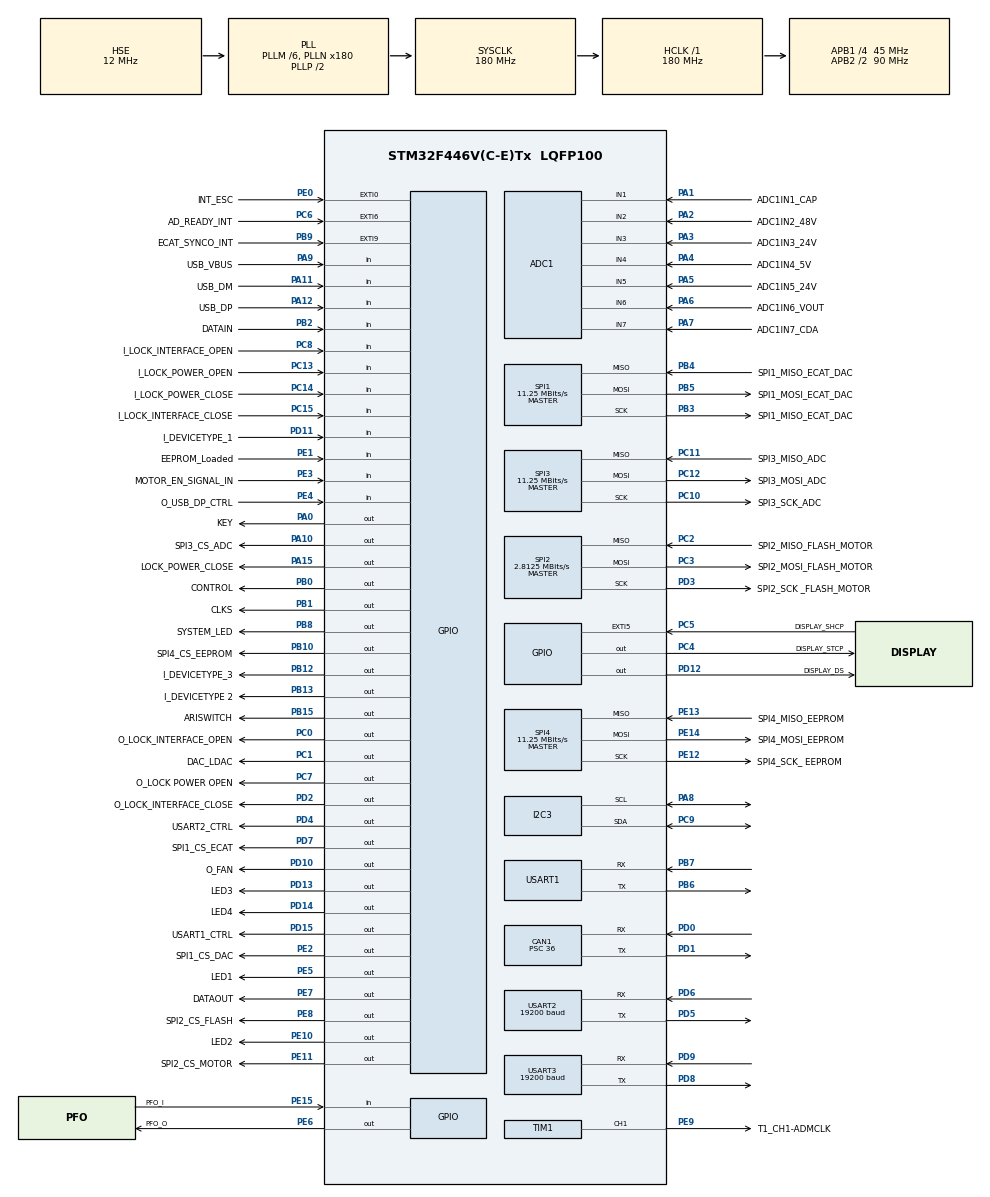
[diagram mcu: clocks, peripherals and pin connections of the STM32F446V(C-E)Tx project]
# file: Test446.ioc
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ADC1.Channel-0\#ChannelRegularConversion=ADC_CHANNEL_1
ADC1.Channel-1\#ChannelRegularConversion=ADC_CHANNEL_1
ADC1.Channel-2\#ChannelRegularConversion=ADC_CHANNEL_1
ADC1.Channel-3\#ChannelRegularConversion=ADC_CHANNEL_1
ADC1.Channel-4\#ChannelRegularConversion=ADC_CHANNEL_1
ADC1.Channel-5\#ChannelRegularConversion=ADC_CHANNEL_1
ADC1.Channel-6\#ChannelRegularConversion=ADC_CHANNEL_1
ADC1.ContinuousConvMode=ENABLE
ADC1.master=1
ADC1.NbrOfConversion=7
ADC1.NbrOfConversionFlag=1
ADC1.Rank-0\#ChannelRegularConversion=1
ADC1.Rank-1\#ChannelRegularConversion=2
ADC1.Rank-2\#ChannelRegularConversion=3
ADC1.Rank-3\#ChannelRegularConversion=4
ADC1.Rank-4\#ChannelRegularConversion=5
ADC1.Rank-5\#ChannelRegularConversion=6
ADC1.Rank-6\#ChannelRegularConversion=7
ADC1.SamplingTime-0\#ChannelRegularConversion=ADC_SAMPLETIME_3CYCLES
ADC1.SamplingTime-1\#ChannelRegularConversion=ADC_SAMPLETIME_3CYCLES
ADC1.SamplingTime-2\#ChannelRegularConversion=ADC_SAMPLETIME_3CYCLES
ADC1.SamplingTime-3\#ChannelRegularConversion=ADC_SAMPLETIME_3CYCLES
ADC1.SamplingTime-4\#ChannelRegularConversion=ADC_SAMPLETIME_3CYCLES
ADC1.SamplingTime-5\#ChannelRegularConversion=ADC_SAMPLETIME_3CYCLES
ADC1.SamplingTime-6\#ChannelRegularConversion=ADC_SAMPLETIME_3CYCLES
ADC1.ScanConvMode=ENABLE
board=custom
CAN1.ABOM=ENABLE
CAN1.BS1=CAN_BS1_4TQ
CAN1.BS2=CAN_BS2_5TQ
CAN1.CalculateBaudRate=125000
CAN1.CalculateTimeBit=8000
CAN1.CalculateTimeQuantum=800.0
CAN1.NART=ENABLE
CAN1.Prescaler=36
CAN1.RFLM=ENABLE
CAN1.TTCM=ENABLE
Dma.ADC1.0.Direction=DMA_PERIPH_TO_MEMORY
Dma.ADC1.0.FIFOMode=DMA_FIFOMODE_DISABLE
Dma.ADC1.0.Instance=DMA2_Stream0
Dma.ADC1.0.MemDataAlignment=DMA_MDATAALIGN_WORD
Dma.ADC1.0.MemInc=DMA_MINC_ENABLE
Dma.ADC1.0.Mode=DMA_CIRCULAR
Dma.ADC1.0.PeriphDataAlignment=DMA_PDATAALIGN_WORD
Dma.ADC1.0.PeriphInc=DMA_PINC_DISABLE
Dma.ADC1.0.Priority=DMA_PRIORITY_LOW
Dma.I2C3_RX.1.Direction=DMA_PERIPH_TO_MEMORY
Dma.I2C3_RX.1.FIFOMode=DMA_FIFOMODE_DISABLE
Dma.I2C3_RX.1.Instance=DMA1_Stream1
Dma.I2C3_RX.1.MemDataAlignment=DMA_MDATAALIGN_BYTE
Dma.I2C3_RX.1.MemInc=DMA_MINC_ENABLE
Dma.I2C3_RX.1.Mode=DMA_NORMAL
Dma.I2C3_RX.1.PeriphDataAlignment=DMA_PDATAALIGN_BYTE
Dma.I2C3_RX.1.PeriphInc=DMA_PINC_DISABLE
Dma.I2C3_RX.1.Priority=DMA_PRIORITY_LOW
Dma.I2C3_TX.2.Direction=DMA_MEMORY_TO_PERIPH
Dma.I2C3_TX.2.FIFOMode=DMA_FIFOMODE_DISABLE
Dma.I2C3_TX.2.Instance=DMA1_Stream4
Dma.I2C3_TX.2.MemDataAlignment=DMA_MDATAALIGN_BYTE
Dma.I2C3_TX.2.MemInc=DMA_MINC_ENABLE
Dma.I2C3_TX.2.Mode=DMA_NORMAL
Dma.I2C3_TX.2.PeriphDataAlignment=DMA_PDATAALIGN_BYTE
Dma.I2C3_TX.2.PeriphInc=DMA_PINC_DISABLE
Dma.I2C3_TX.2.Priority=DMA_PRIORITY_LOW
Dma.Request0=ADC1
Dma.Request1=I2C3_RX
Dma.Request2=I2C3_TX
FREERTOS.INCLUDE_vTaskCleanUpResources=0
FREERTOS.Tasks01=defaultTask,40,512,StartDefaultTask,As weak,NULL,Dynamic,NULL,NULL;LDETask,8,128,StartTask03,As weak,NULL,Dynamic,NULL,NULL;RS485Task,40,256,TASK_RS485,As weak,NULL,Dynamic,NULL,NULL;DeviceNetTask,24,512,TASK_DeviceNet,As weak,NULL,Dynamic,NULL,NULL;HcmsTask,8,128,Task_Hcms,As weak,NULL,Dynamic,NULL,NULL;RS232Task,40,256,TASK_RS232,As weak,NULL,Dynamic,NULL,NULL;FlowEstTAask,16,128,Task_FlowEst,As weak,NULL,Dynamic,NULL,NULL;AdaptiveTask,16,256,Task_Adapyive,As weak,NULL,Dynamic,NULL,NULL;EtherCATTask,40,256,TASK_EtherCAT,As weak,NULL,Dynamic,NULL,NULL;RS485_2,40,256,TASK_RS485_2,As weak,NULL,Dynamic,NULL,NULL;USBTask,40,768,TASK_USB,As weak,NULL,Dynamic,NULL,NULL;USBIOTask,40,512,TASK_USB_IO,As weak,NULL,Dynamic,NULL,NULL
FREERTOS.TOTAL_HEAP_SIZE=20480
IWDG.Prescaler=IWDG_PRESCALER_32
Mcu.Family=STM32F4
Mcu.Name=STM32F446V(C-E)Tx
Mcu.Package=LQFP100
NVIC.CAN1_RX0_IRQn=true\:5\:0\:false\:false\:true\:true\:true\:true\:true
NVIC.DMA1_Stream1_IRQn=true\:5\:0\:false\:false\:true\:true\:false\:true\:true
NVIC.DMA1_Stream4_IRQn=true\:5\:0\:false\:false\:true\:true\:false\:true\:true
NVIC.DMA2_Stream0_IRQn=true\:5\:0\:false\:false\:true\:true\:false\:true\:true
NVIC.I2C3_ER_IRQn=true\:5\:0\:false\:false\:true\:true\:true\:true\:true
NVIC.I2C3_EV_IRQn=true\:5\:0\:false\:false\:true\:true\:true\:true\:true
NVIC.OTG_FS_IRQn=true\:5\:0\:false\:false\:true\:true\:true\:true\:true
NVIC.PriorityGroup=NVIC_PRIORITYGROUP_4
NVIC.TIM1_UP_TIM10_IRQn=true\:5\:0\:false\:false\:true\:true\:true\:true\:true
NVIC.TIM3_IRQn=true\:5\:0\:false\:false\:true\:true\:true\:true\:true
NVIC.TIM7_IRQn=true\:15\:0\:false\:false\:true\:false\:false\:true\:true
NVIC.TimeBase=TIM7_IRQn
NVIC.TimeBaseIP=TIM7
NVIC.USART1_IRQn=true\:5\:0\:false\:false\:true\:true\:true\:true\:true
NVIC.USART2_IRQn=true\:5\:0\:false\:false\:true\:true\:true\:true\:true
NVIC.USART3_IRQn=true\:5\:0\:false\:false\:true\:true\:true\:true\:true
PA0-WKUP.GPIO_Label=KEY
PA0-WKUP.Signal=GPIO_Output
PA1.GPIO_Label=ADC1IN1_CAP
PA1.Signal=ADCx_IN1
PA10.GPIO_Label=SPI3_CS_ADC
PA10.Signal=GPIO_Output
PA11.GPIO_Label=USB_DM
PA11.GPIO_PuPd=GPIO_NOPULL
PA11.Signal=GPIO_Input
PA12.GPIO_Label=USB_DP
PA12.GPIO_PuPd=GPIO_NOPULL
PA12.Signal=GPIO_Input
PA13.Mode=Serial_Wire
PA13.Signal=SYS_JTMS-SWDIO
PA14.Mode=Serial_Wire
PA14.Signal=SYS_JTCK-SWCLK
PA15.GPIO_Label=LOCK_POWER_CLOSE
PA15.Signal=GPIO_Output
PA2.GPIO_Label=ADC1IN2_48V
PA2.Signal=ADCx_IN2
PA3.GPIO_Label=ADC1IN3_24V
PA3.Signal=ADCx_IN3
PA4.GPIO_Label=ADC1IN4_5V
PA4.Signal=ADCx_IN4
PA5.GPIO_Label=ADC1IN5_24V
PA5.Signal=ADCx_IN5
PA6.GPIO_Label=ADC1IN6_VOUT
PA6.Signal=ADCx_IN6
PA7.GPIO_Label=ADC1IN7_CDA
PA7.Signal=ADCx_IN7
PA8.GPIO_Pu=GPIO_PULLUP
PA8.Mode=I2C
PA8.Signal=I2C3_SCL
PA9.GPIO_Label=USB_VBUS
PA9.GPIO_PuPd=GPIO_NOPULL
PA9.Signal=GPIO_Input
PB0.GPIO_Label=CONTROL
PB0.Signal=GPIO_Output
PB1.GPIO_Label=CLKS
PB1.Signal=GPIO_Output
PB10.GPIO_Label=SPI4_CS_EEPROM
PB10.Signal=GPIO_Output
PB12.GPIO_Label=I_DEVICETYPE_3
PB12.Signal=GPIO_Output
PB13.GPIO_Label=I_DEVICETYPE 2
PB13.Signal=GPIO_Output
PB15.GPIO_Label=ARISWITCH
PB15.Signal=GPIO_Output
PB2.GPIO_Label=DATAIN
PB2.Signal=GPIO_Input
PB3.GPIO_Label=SPI1_MISO_ECAT_DAC
PB3.GPIO_PuPd=GPIO_PULLUP
PB3.Mode=Full_Duplex_Master
PB3.Signal=SPI1_SCK
PB4.GPIO_Label=SPI1_MISO_ECAT_DAC
PB4.GPIO_PuPd=GPIO_PULLUP
PB4.Mode=Full_Duplex_Master
PB4.Signal=SPI1_MISO
PB5.GPIO_Label=SPI1_MOSI_ECAT_DAC
PB5.GPIO_PuPd=GPIO_PULLUP
PB5.Mode=Full_Duplex_Master
PB5.Signal=SPI1_MOSI
PB6.Mode=Asynchronous
PB6.Signal=USART1_TX
PB7.Mode=Asynchronous
PB7.Signal=USART1_RX
PB8.GPIO_Label=SYSTEM_LED
PB8.Signal=GPIO_Output
PB9.GPIO_Label=ECAT_SYNCO_INT
PB9.Signal=GPXTI9
PC0.GPIO_Label=O_LOCK_INTERFACE_OPEN
PC0.Signal=GPIO_Output
PC1.GPIO_Label=DAC_LDAC
PC1.Signal=GPIO_Output
PC10.GPIO_Label=SPI3_SCK_ADC
PC10.GPIO_PuPd=GPIO_PULLUP
PC10.Mode=Full_Duplex_Master
PC10.Signal=SPI3_SCK
PC11.GPIO_Label=SPI3_MISO_ADC
PC11.GPIO_PuPd=GPIO_PULLUP
PC11.Mode=Full_Duplex_Master
PC11.Signal=SPI3_MISO
PC12.GPIO_Label=SPI3_MOSI_ADC
PC12.GPIO_PuPd=GPIO_PULLUP
PC12.Mode=Full_Duplex_Master
PC12.Signal=SPI3_MOSI
PC13.GPIO_Label=I_LOCK_POWER_OPEN
PC13.Signal=GPIO_Input
PC14-OSC32_IN.GPIO_Label=I_LOCK_POWER_CLOSE
PC14-OSC32_IN.Signal=GPIO_Input
PC15-OSC32_OUT.GPIO_Label=I_LOCK_INTERFACE_CLOSE
PC15-OSC32_OUT.Signal=GPIO_Input
PC2.GPIO_Label=SPI2_MISO_FLASH_MOTOR
PC2.GPIO_PuPd=GPIO_PULLUP
PC2.Mode=Full_Duplex_Master
PC2.Signal=SPI2_MISO
PC3.GPIO_Label=SPI2_MOSI_FLASH_MOTOR
PC3.GPIO_PuPd=GPIO_PULLUP
PC3.Mode=Full_Duplex_Master
PC3.Signal=SPI2_MOSI
PC4.GPIO_Label=DISPLAY_STCP
PC4.Signal=GPIO_Output
PC5.GPIO_Label=DISPLAY_SHCP
PC5.Signal=GPXTI5
PC6.GPIO_Label=AD_READY_INT
PC6.Signal=GPXTI6
PC7.GPIO_Label=O_LOCK POWER OPEN
PC7.Signal=GPIO_Output
PC8.GPIO_Label=I_LOCK_INTERFACE_OPEN
PC8.Signal=GPIO_Input
PC9.GPIO_Pu=GPIO_PULLUP
PC9.Mode=I2C
PC9.Signal=I2C3_SDA
PD0.GPIO_PuPd=GPIO_NOPULL
PD0.Mode=CAN_Activate
PD0.Signal=CAN1_RX
PD1.GPIO_PuPd=GPIO_NOPULL
PD1.Mode=CAN_Activate
PD1.Signal=CAN1_TX
PD10.GPIO_Label=O_FAN
PD10.Signal=GPIO_Output
PD11.GPIO_Label=I_DEVICETYPE_1
PD11.Signal=GPIO_Input
PD12.GPIO_Label=DISPLAY_DS
PD12.Signal=GPIO_Output
PD13.GPIO_Label=LED3
PD13.Signal=GPIO_Output
PD14.GPIO_Label=LED4
PD14.Signal=GPIO_Output
PD15.GPIO_Label=USART1_CTRL
PD15.Signal=GPIO_Output
PD2.GPIO_Label=O_LOCK_INTERFACE_CLOSE
PD2.GPIO_PuPd=GPIO_PULLUP
PD2.Signal=GPIO_Output
PD3.GPIO_Label=SPI2_SCK _FLASH_MOTOR
PD3.GPIO_PuPd=GPIO_PULLUP
PD3.Mode=Full_Duplex_Master
PD3.Signal=SPI2_SCK
PD4.GPIO_Label=USART2_CTRL
PD4.Signal=GPIO_Output
PD5.Mode=Asynchronous
PD5.Signal=USART2_TX
PD6.Mode=Asynchronous
PD6.Signal=USART2_RX
PD7.GPIO_Label=SPI1_CS_ECAT
PD7.Signal=GPIO_Output
PD8.Mode=Asynchronous
PD8.Signal=USART3_TX
PD9.Mode=Asynchronous
PD9.Signal=USART3_RX
PE0.GPIO_Label=INT_ESC
PE0.Signal=GPXTI0
PE1.GPIO_Label=EEPROM_Loaded
PE1.Signal=GPIO_Input
PE10.GPIO_Label=LED2
PE10.Signal=GPIO_Output
PE11.GPIO_Label=SPI2_CS_MOTOR
PE11.PinState=GPIO_PIN_SET
PE11.Signal=GPIO_Output
PE12.GPIO_Label=SPI4_SCK_ EEPROM
PE12.GPIO_PuPd=GPIO_PULLUP
PE12.Mode=Full_Duplex_Master
PE12.Signal=SPI4_SCK
PE13.GPIO_Label=SPI4_MISO_EEPROM
PE13.GPIO_PuPd=GPIO_PULLUP
PE13.Mode=Full_Duplex_Master
PE13.Signal=SPI4_MISO
PE14.GPIO_Label=SPI4_MOSI_EEPROM
PE14.GPIO_PuPd=GPIO_PULLUP
PE14.Mode=Full_Duplex_Master
PE14.Signal=SPI4_MOSI
PE15.GPIO_Label=PFO_I
PE15.Signal=GPIO_Input
PE2.GPIO_Label=SPI1_CS_DAC
PE2.Signal=GPIO_Output
PE3.GPIO_Label=MOTOR_EN_SIGNAL_IN
PE3.Signal=GPIO_Input
PE4.GPIO_Label=O_USB_DP_CTRL
PE4.GPIO_PuPd=GPIO_NOPULL
PE4.Signal=GPIO_Input
PE5.GPIO_Label=LED1
PE5.Signal=GPIO_Output
PE6.GPIO_Label=PFO_O
PE6.Signal=GPIO_Output
PE7.GPIO_Label=DATAOUT
PE7.Signal=GPIO_Output
PE8.GPIO_Label=SPI2_CS_FLASH
PE8.PinState=GPIO_PIN_SET
PE8.Signal=GPIO_Output
PE9.GPIO_Label=T1_CH1-ADMCLK
PE9.GPIO_PuPd=GPIO_PULLUP
PE9.GPIO_Speed=GPIO_SPEED_FREQ_VERY_HIGH
PE9.Signal=S_TIM1_CH1
PH0-OSC_IN.Mode=HSE-External-Clock-Source
PH0-OSC_IN.Signal=RCC_OSC_IN
PH1-OSC_OUT.Mode=HSE-External-Clock-Source
PH1-OSC_OUT.Signal=RCC_OSC_OUT
ProjectManager.HeapSize=0x200
ProjectManager.StackSize=0x500
ProjectManager.TargetToolchain=STM32CubeIDE
RCC.AHBFreq_Value=180000000
RCC.APB1CLKDivider=RCC_HCLK_DIV4
RCC.APB1Freq_Value=45000000
RCC.APB1TimFreq_Value=90000000
RCC.APB2CLKDivider=RCC_HCLK_DIV2
RCC.APB2Freq_Value=90000000
RCC.APB2TimFreq_Value=180000000
RCC.CortexFreq_Value=180000000
RCC.HCLKFreq_Value=180000000
RCC.HSE_VALUE=12000000
RCC.PLLM=6
RCC.PLLN=180
RCC.PLLQ=3
RCC.PLLSAIM=6
RCC.PLLSAIN=96
RCC.PLLSAIP=RCC_PLLSAIP_DIV4
RCC.PWR_Regulator_Voltage_Scale=PWR_REGULATOR_VOLTAGE_SCALE1
RCC.PWREXT_OverDrive=PWREXT_OverDrive_ACTIVATED
RCC.SYSCLKFreq_VALUE=180000000
RCC.SYSCLKSource=RCC_SYSCLKSOURCE_PLLCLK
RCC.USBCLockSelection=RCC_CLK48CLKSOURCE_PLLSAIP
RCC.USBFreq_Value=48000000
RCC.VCOOutputFreq_Value=360000000
SH.ADCx_IN1.0=ADC1_IN1,IN1
SH.ADCx_IN2.0=ADC1_IN2,IN2
SH.ADCx_IN3.0=ADC1_IN3,IN3
SH.ADCx_IN4.0=ADC1_IN4,IN4
SH.ADCx_IN5.0=ADC1_IN5,IN5
SH.ADCx_IN6.0=ADC1_IN6,IN6
SH.ADCx_IN7.0=ADC1_IN7,IN7
SH.S_TIM1_CH1.0=TIM1_CH1,PWM Generation1 CH1
SPI1.BaudRatePrescaler=SPI_BAUDRATEPRESCALER_8
SPI1.CalculateBaudRate=11.25 MBits/s
SPI1.CLKPhase=SPI_PHASE_2EDGE
SPI1.CLKPolarity=SPI_POLARITY_HIGH
SPI1.Direction=SPI_DIRECTION_2LINES
SPI1.Mode=SPI_MODE_MASTER
SPI1.VirtualType=VM_MASTER
SPI2.BaudRatePrescaler=SPI_BAUDRATEPRESCALER_16
SPI2.CalculateBaudRate=2.8125 MBits/s
SPI2.Direction=SPI_DIRECTION_2LINES
SPI2.Mode=SPI_MODE_MASTER
SPI2.VirtualType=VM_MASTER
SPI3.BaudRatePrescaler=SPI_BAUDRATEPRESCALER_4
SPI3.CalculateBaudRate=11.25 MBits/s
SPI3.CLKPhase=SPI_PHASE_2EDGE
SPI3.Direction=SPI_DIRECTION_2LINES
SPI3.Mode=SPI_MODE_MASTER
SPI3.VirtualType=VM_MASTER
SPI4.BaudRatePrescaler=SPI_BAUDRATEPRESCALER_8
SPI4.CalculateBaudRate=11.25 MBits/s
SPI4.Direction=SPI_DIRECTION_2LINES
SPI4.Mode=SPI_MODE_MASTER
SPI4.VirtualType=VM_MASTER
TIM1.Channel-PWM\ Generation1\ CH1=TIM_CHANNEL_1
TIM1.Period=22
TIM1.Prescaler=0
TIM1.Pulse-PWM\ Generation1\ CH1=11
TIM10.Period=59999
TIM10.Prescaler=180-1
TIM3.Period=99
TIM3.Prescaler=89
USART1.VirtualMode=VM_ASYNC
USART2.BaudRate=19200
USART2.VirtualMode=VM_ASYNC
USART3.BaudRate=19200
USART3.VirtualMode=VM_ASYNC
VP_FREERTOS_VS_CMSIS_V2.Mode=CMSIS_V2
VP_IWDG_VS_IWDG.Mode=IWDG_Activate
VP_SYS_VS_tim7.Mode=TIM7
VP_TIM1_VS_ClockSourceINT.Mode=Internal
VP_TIM10_VS_ClockSourceINT.Mode=Enable_Timer
VP_TIM11_VS_ClockSourceINT.Mode=Enable_Timer
VP_TIM12_VS_ClockSourceINT.Mode=Internal
VP_TIM3_VS_ClockSourceINT.Mode=Internal
VP_TIM9_VS_ClockSourceINT.Mode=Internal
RCC.PLLSourceVirtual=RCC_PLLSOURCE_HSE

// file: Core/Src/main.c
/* USER CODE BEGIN Header */
/**
  ******************************************************************************
  * @file           : main.c
  * @brief          : Main program body
  ******************************************************************************
  * @attention
  *
  * Copyright (c) 2025 STMicroelectronics.
  * All rights reserved.
  *
  * This software is licensed under terms that can be found in the LICENSE file
  * in the root directory of this software component.
  * If no LICENSE file comes with this software, it is provided AS-IS.
  *
  ******************************************************************************
  */
/* USER CODE END Header */
#include "main.h"
#include "cmsis_os.h"

/* USER CODE BEGIN Includes */
#include "usb_app.h"
#include "usb_media.h"
#include "usb_io.h"
#include "spi2_bus.h"
#include "board.h"
#include "FreeRTOS.h"
#include "task.h"

/* USER CODE END Includes */

ADC_HandleTypeDef hadc1;
DMA_HandleTypeDef hdma_adc1;

CAN_HandleTypeDef hcan1;

I2C_HandleTypeDef hi2c3;
DMA_HandleTypeDef hdma_i2c3_rx;
DMA_HandleTypeDef hdma_i2c3_tx;

IWDG_HandleTypeDef hiwdg;

SPI_HandleTypeDef hspi1;
SPI_HandleTypeDef hspi2;
SPI_HandleTypeDef hspi3;
SPI_HandleTypeDef hspi4;

TIM_HandleTypeDef htim1;
TIM_HandleTypeDef htim3;
TIM_HandleTypeDef htim9;
TIM_HandleTypeDef htim10;
TIM_HandleTypeDef htim11;
TIM_HandleTypeDef htim12;

UART_HandleTypeDef huart1;
UART_HandleTypeDef huart2;
UART_HandleTypeDef huart3;

/* Definitions for defaultTask */
osThreadId_t defaultTaskHandle;
const osThreadAttr_t defaultTask_attributes = {
  .name = "defaultTask",
  .stack_size = 512 * 4,
  .priority = (osPriority_t) osPriorityHigh,
};
/* Definitions for LDETask */
osThreadId_t LDETaskHandle;
const osThreadAttr_t LDETask_attributes = {
  .name = "LDETask",
  .stack_size = 128 * 4,
  .priority = (osPriority_t) osPriorityLow,
};
/* Definitions for RS485Task */
osThreadId_t RS485TaskHandle;
const osThreadAttr_t RS485Task_attributes = {
  .name = "RS485Task",
  .stack_size = 256 * 4,
  .priority = (osPriority_t) osPriorityHigh,
};
/* Definitions for DeviceNetTask */
osThreadId_t DeviceNetTaskHandle;
const osThreadAttr_t DeviceNetTask_attributes = {
  .name = "DeviceNetTask",
  .stack_size = 512 * 4,
  .priority = (osPriority_t) osPriorityNormal,
};
/* Definitions for HcmsTask */
osThreadId_t HcmsTaskHandle;
const osThreadAttr_t HcmsTask_attributes = {
  .name = "HcmsTask",
  .stack_size = 128 * 4,
  .priority = (osPriority_t) osPriorityLow,
};
/* Definitions for RS232Task */
osThreadId_t RS232TaskHandle;
const osThreadAttr_t RS232Task_attributes = {
  .name = "RS232Task",
  .stack_size = 256 * 4,
  .priority = (osPriority_t) osPriorityHigh,
};
/* Definitions for FlowEstTAask */
osThreadId_t FlowEstTAaskHandle;
const osThreadAttr_t FlowEstTAask_attributes = {
  .name = "FlowEstTAask",
  .stack_size = 128 * 4,
  .priority = (osPriority_t) osPriorityBelowNormal,
};
/* Definitions for AdaptiveTask */
osThreadId_t AdaptiveTaskHandle;
const osThreadAttr_t AdaptiveTask_attributes = {
  .name = "AdaptiveTask",
  .stack_size = 256 * 4,
  .priority = (osPriority_t) osPriorityBelowNormal,
};
/* Definitions for EtherCATTask */
osThreadId_t EtherCATTaskHandle;
const osThreadAttr_t EtherCATTask_attributes = {
  .name = "EtherCATTask",
  .stack_size = 256 * 4,
  .priority = (osPriority_t) osPriorityHigh,
};
/* Definitions for RS485_2 */
osThreadId_t RS485_2Handle;
const osThreadAttr_t RS485_2_attributes = {
  .name = "RS485_2",
  .stack_size = 256 * 4,
  .priority = (osPriority_t) osPriorityHigh,
};
/* Definitions for USBTask */
osThreadId_t USBTaskHandle;
const osThreadAttr_t USBTask_attributes = {
  .name = "USBTask",
  .stack_size = 3072,
  .priority = (osPriority_t) osPriorityHigh,
};
/* Definitions for USBIOTask */
osThreadId_t USBIOTaskHandle;
const osThreadAttr_t USBIOTask_attributes = {
  .name = "USB_IO", .stack_size = 2048, .priority = osPriorityHigh
};
/* USER CODE BEGIN PV */
static volatile bool usb_app_ready;
static volatile uint32_t usb_io_progress;
volatile uint32_t g_usb_min_heap, g_usb_worker_stack_free, g_usb_io_stack_free;

/* USER CODE END PV */

void SystemClock_Config(void);
static void MX_GPIO_Init(void);
static void MX_DMA_Init(void);
static void MX_CAN1_Init(void);
static void MX_TIM1_Init(void);
static void MX_ADC1_Init(void);
static void MX_IWDG_Init(void);
static void MX_I2C3_Init(void);
static void MX_TIM3_Init(void);
static void MX_TIM9_Init(void);
static void MX_TIM10_Init(void);
static void MX_TIM11_Init(void);
static void MX_TIM12_Init(void);
static void MX_SPI1_Init(void);
static void MX_SPI2_Init(void);
static void MX_SPI3_Init(void);
static void MX_SPI4_Init(void);
static void MX_USART1_UART_Init(void);
static void MX_USART2_UART_Init(void);
static void MX_USART3_UART_Init(void);

void StartDefaultTask(void *argument);
void StartTask03(void *argument);
void TASK_RS485(void *argument);
void TASK_DeviceNet(void *argument);
void Task_Hcms(void *argument);
void TASK_RS232(void *argument);
void Task_FlowEst(void *argument);
void Task_Adapyive(void *argument);
void TASK_EtherCAT(void *argument);
void TASK_RS485_2(void *argument);
void TASK_USB(void *argument);
void TASK_USB_IO(void *argument);

/* USER CODE BEGIN 0 */

/* 未完成的 RS485 示例按本次授权注释，原文保留。
unsigned char cCommFix = 0;

void API_GetSerialRxData(unsigned char *p_rxbuffer, unsigned char *p_size, unsigned char *p_rxtxflag)
{
	unsigned char * dst;
	if (*p_rxtxflag == 1) {
		*p_rxtxflag = 2;
		dst = Uart1. rcvbufb;
		for (unsigned char i= 0; i< *p_size; i++) {
			* dst++ = *p_rxbuffer++;
		}
	Uart1.rcvlen = *p_size;
}

void API_SetserialTxData(unsigned char *p_txbuffer, unsigned char *p_size, unsigned char *p_rxtxflag)
{
	unsigned char *src;
	unsigned char temp;

	if(Uart1.flags & PACKET_TRASH) {
		Uart1.flags &= ~PACKET_TRASH;
		*p_size = Uart1.xmtlen;
		__HAL_UART_DISABLE_IT(&huart1, UART_IT_TC);
		__HAL_UART_CLEAR_FLAG (&huart1, UART_FLAG_TC);
		temp = huart1.Instance->DR;
		__HAL_UART_ENABLE_IT(&huart1, UART_IT_RXNE);
		__HAL_UART_ENABLE_IT(&huart1, UART_IT_IDLE);
		*p_rxtxflag = 0;
	} else if(Uart1.xmtlen > 0) {
		if(!(Uart1.flags & TX_PENDING)) {
			*p_size = Uart1.xmtlen;
			Uart1.xmtlen = 0;
			src = Uart1.xmtbuf;
			for (unsigned char i= 0; i< *p_size; i++) {
				*p_txbuffer++ = *src++;
			}
			MAIN_ucSerialTxCount = 0;
			if(cCommFix != 0x00) {
				huart1.Instance->DR = cCommFix;
			} else {
				huart1.Instance->DR = Uart1.xmtbuf[MAIN_ucSerialTxCount++];
			}
			if(Uart1.flags & PACKET_FAULT) {
				Uart1.flags &= ~PACKET_FAULT;
			}
		}
	} else {
		//do nothing
	}
}

*/

/* USER CODE END 0 */

int main(void)
{

  /* MCU Configuration--------------------------------------------------------*/

  /* Reset of all peripherals, Initializes the Flash interface and the Systick. */
  HAL_Init();

  /* Configure the system clock */
  SystemClock_Config();

  /* Initialize all configured peripherals */
  MX_GPIO_Init();
  MX_DMA_Init();
  MX_CAN1_Init();
  MX_TIM1_Init();
  MX_ADC1_Init();
  MX_IWDG_Init();
  MX_I2C3_Init();
  MX_TIM3_Init();
  MX_TIM9_Init();
  MX_TIM10_Init();
  MX_TIM11_Init();
  MX_TIM12_Init();
  MX_SPI1_Init();
  MX_SPI2_Init();
  MX_SPI3_Init();
  MX_SPI4_Init();
  MX_USART1_UART_Init();
  MX_USART2_UART_Init();
  MX_USART3_UART_Init();

  /* Init scheduler */
  osKernelInitialize();

  /* USER CODE BEGIN RTOS_MUTEX */
  usb_io_init();
  if (!usb_media_init() || !spi2_bus_init()) Error_Handler();
  /* USER CODE END RTOS_MUTEX */

  /* Create the thread(s) */
  /* creation of defaultTask */
  defaultTaskHandle = osThreadNew(StartDefaultTask, NULL, &defaultTask_attributes);

  /* creation of LDETask */
  LDETaskHandle = osThreadNew(StartTask03, NULL, &LDETask_attributes);

  /* creation of RS485Task */
  RS485TaskHandle = osThreadNew(TASK_RS485, NULL, &RS485Task_attributes);

  /* creation of DeviceNetTask */
  DeviceNetTaskHandle = osThreadNew(TASK_DeviceNet, NULL, &DeviceNetTask_attributes);

  /* creation of HcmsTask */
  HcmsTaskHandle = osThreadNew(Task_Hcms, NULL, &HcmsTask_attributes);

  /* creation of RS232Task */
  RS232TaskHandle = osThreadNew(TASK_RS232, NULL, &RS232Task_attributes);

  /* creation of FlowEstTAask */
  FlowEstTAaskHandle = osThreadNew(Task_FlowEst, NULL, &FlowEstTAask_attributes);

  /* creation of AdaptiveTask */
  AdaptiveTaskHandle = osThreadNew(Task_Adapyive, NULL, &AdaptiveTask_attributes);

  /* creation of EtherCATTask */
  EtherCATTaskHandle = osThreadNew(TASK_EtherCAT, NULL, &EtherCATTask_attributes);

  /* creation of RS485_2 */
  RS485_2Handle = osThreadNew(TASK_RS485_2, NULL, &RS485_2_attributes);

  /* creation of USBTask */
  USBTaskHandle = osThreadNew(TASK_USB, NULL, &USBTask_attributes);

  /* creation of USBIOTask */
  USBIOTaskHandle = osThreadNew(TASK_USB_IO, NULL, &USBIOTask_attributes);

  /* USER CODE BEGIN RTOS_THREADS */

  if (!defaultTaskHandle || !LDETaskHandle || !RS485TaskHandle || !DeviceNetTaskHandle ||
      !HcmsTaskHandle || !RS232TaskHandle || !FlowEstTAaskHandle || !AdaptiveTaskHandle ||
      !EtherCATTaskHandle || !RS485_2Handle || !USBTaskHandle || !USBIOTaskHandle) Error_Handler();
  /* USER CODE END RTOS_THREADS */

  /* Start scheduler */
  osKernelStart();

  /* We should never get here as control is now taken by the scheduler */

  /* Infinite loop */
  while (1)
  {

  }
}

void SystemClock_Config(void)
{
  RCC_OscInitTypeDef RCC_OscInitStruct = {0};
  RCC_ClkInitTypeDef RCC_ClkInitStruct = {0};

  /** Configure the main internal regulator output voltage
  */
  __HAL_RCC_PWR_CLK_ENABLE();
  __HAL_PWR_VOLTAGESCALING_CONFIG(PWR_REGULATOR_VOLTAGE_SCALE1);

  /** Initializes the RCC Oscillators according to the specified parameters
  * in the RCC_OscInitTypeDef structure.
  */
  RCC_OscInitStruct.OscillatorType = RCC_OSCILLATORTYPE_LSI|RCC_OSCILLATORTYPE_HSE;
  RCC_OscInitStruct.HSEState = RCC_HSE_BYPASS;
  RCC_OscInitStruct.LSIState = RCC_LSI_ON;
  RCC_OscInitStruct.PLL.PLLState = RCC_PLL_ON;
  RCC_OscInitStruct.PLL.PLLSource = RCC_PLLSOURCE_HSE;
  RCC_OscInitStruct.PLL.PLLM = 6;
  RCC_OscInitStruct.PLL.PLLN = 180;
  RCC_OscInitStruct.PLL.PLLP = RCC_PLLP_DIV2;
  RCC_OscInitStruct.PLL.PLLQ = 3;
  RCC_OscInitStruct.PLL.PLLR = 2;
  if (HAL_RCC_OscConfig(&RCC_OscInitStruct) != HAL_OK)
  {
    Error_Handler();
  }

  /** Activate the Over-Drive mode
  */
  if (HAL_PWREx_EnableOverDrive() != HAL_OK)
  {
    Error_Handler();
  }

  /** Initializes the CPU, AHB and APB buses clocks
  */
  RCC_ClkInitStruct.ClockType = RCC_CLOCKTYPE_HCLK|RCC_CLOCKTYPE_SYSCLK
                              |RCC_CLOCKTYPE_PCLK1|RCC_CLOCKTYPE_PCLK2;
  RCC_ClkInitStruct.SYSCLKSource = RCC_SYSCLKSOURCE_PLLCLK;
  RCC_ClkInitStruct.AHBCLKDivider = RCC_SYSCLK_DIV1;
  RCC_ClkInitStruct.APB1CLKDivider = RCC_HCLK_DIV4;
  RCC_ClkInitStruct.APB2CLKDivider = RCC_HCLK_DIV2;

  if (HAL_RCC_ClockConfig(&RCC_ClkInitStruct, FLASH_LATENCY_5) != HAL_OK)
  {
    Error_Handler();
  }
}

static void MX_ADC1_Init(void)
{

  ADC_ChannelConfTypeDef sConfig = {0};

  /** Configure the global features of the ADC (Clock, Resolution, Data Alignment and number of conversion)
  */
  hadc1.Instance = ADC1;
  hadc1.Init.ClockPrescaler = ADC_CLOCK_SYNC_PCLK_DIV4;
  hadc1.Init.Resolution = ADC_RESOLUTION_12B;
  hadc1.Init.ScanConvMode = ENABLE;
  hadc1.Init.ContinuousConvMode = ENABLE;
  hadc1.Init.DiscontinuousConvMode = DISABLE;
  hadc1.Init.ExternalTrigConvEdge = ADC_EXTERNALTRIGCONVEDGE_NONE;
  hadc1.Init.ExternalTrigConv = ADC_SOFTWARE_START;
  hadc1.Init.DataAlign = ADC_DATAALIGN_RIGHT;
  hadc1.Init.NbrOfConversion = 7;
  hadc1.Init.DMAContinuousRequests = DISABLE;
  hadc1.Init.EOCSelection = ADC_EOC_SINGLE_CONV;
  if (HAL_ADC_Init(&hadc1) != HAL_OK)
  {
    Error_Handler();
  }

  /** Configure for the selected ADC regular channel its corresponding rank in the sequencer and its sample time.
  */
  sConfig.Channel = ADC_CHANNEL_1;
  sConfig.Rank = 1;
  sConfig.SamplingTime = ADC_SAMPLETIME_3CYCLES;
  if (HAL_ADC_ConfigChannel(&hadc1, &sConfig) != HAL_OK)
  {
    Error_Handler();
  }

  /** Configure for the selected ADC regular channel its corresponding rank in the sequencer and its sample time.
  */
  sConfig.Rank = 2;
  if (HAL_ADC_ConfigChannel(&hadc1, &sConfig) != HAL_OK)
  {
    Error_Handler();
  }

  /** Configure for the selected ADC regular channel its corresponding rank in the sequencer and its sample time.
  */
  sConfig.Rank = 3;
  if (HAL_ADC_ConfigChannel(&hadc1, &sConfig) != HAL_OK)
  {
    Error_Handler();
  }

  /** Configure for the selected ADC regular channel its corresponding rank in the sequencer and its sample time.
  */
  sConfig.Rank = 4;
  if (HAL_ADC_ConfigChannel(&hadc1, &sConfig) != HAL_OK)
  {
    Error_Handler();
  }

  /** Configure for the selected ADC regular channel its corresponding rank in the sequencer and its sample time.
  */
  sConfig.Rank = 5;
  if (HAL_ADC_ConfigChannel(&hadc1, &sConfig) != HAL_OK)
  {
    Error_Handler();
  }

  /** Configure for the selected ADC regular channel its corresponding rank in the sequencer and its sample time.
  */
  sConfig.Rank = 6;
  if (HAL_ADC_ConfigChannel(&hadc1, &sConfig) != HAL_OK)
  {
    Error_Handler();
  }

  /** Configure for the selected ADC regular channel its corresponding rank in the sequencer and its sample time.
  */
  sConfig.Rank = 7;
  if (HAL_ADC_ConfigChannel(&hadc1, &sConfig) != HAL_OK)
  {
    Error_Handler();
  }

}

static void MX_CAN1_Init(void)
{

  hcan1.Instance = CAN1;
  hcan1.Init.Prescaler = 36;
  hcan1.Init.Mode = CAN_MODE_NORMAL;
  hcan1.Init.SyncJumpWidth = CAN_SJW_1TQ;
  hcan1.Init.TimeSeg1 = CAN_BS1_4TQ;
  hcan1.Init.TimeSeg2 = CAN_BS2_5TQ;
  hcan1.Init.TimeTriggeredMode = ENABLE;
  hcan1.Init.AutoBusOff = ENABLE;
  hcan1.Init.AutoWakeUp = DISABLE;
  hcan1.Init.AutoRetransmission = ENABLE;
  hcan1.Init.ReceiveFifoLocked = ENABLE;
  hcan1.Init.TransmitFifoPriority = DISABLE;
  if (HAL_CAN_Init(&hcan1) != HAL_OK)
  {
    Error_Handler();
  }

}

static void MX_I2C3_Init(void)
{

  hi2c3.Instance = I2C3;
  hi2c3.Init.ClockSpeed = 100000;
  hi2c3.Init.DutyCycle = I2C_DUTYCYCLE_2;
  hi2c3.Init.OwnAddress1 = 0;
  hi2c3.Init.AddressingMode = I2C_ADDRESSINGMODE_7BIT;
  hi2c3.Init.DualAddressMode = I2C_DUALADDRESS_DISABLE;
  hi2c3.Init.OwnAddress2 = 0;
  hi2c3.Init.GeneralCallMode = I2C_GENERALCALL_DISABLE;
  hi2c3.Init.NoStretchMode = I2C_NOSTRETCH_DISABLE;
  if (HAL_I2C_Init(&hi2c3) != HAL_OK)
  {
    Error_Handler();
  }

}

static void MX_IWDG_Init(void)
{

  hiwdg.Instance = IWDG;
  hiwdg.Init.Prescaler = IWDG_PRESCALER_32;
  hiwdg.Init.Reload = 4095;
  if (HAL_IWDG_Init(&hiwdg) != HAL_OK)
  {
    Error_Handler();
  }

}

static void MX_SPI1_Init(void)
{

  /* SPI1 parameter configuration*/
  hspi1.Instance = SPI1;
  hspi1.Init.Mode = SPI_MODE_MASTER;
  hspi1.Init.Direction = SPI_DIRECTION_2LINES;
  hspi1.Init.DataSize = SPI_DATASIZE_8BIT;
  hspi1.Init.CLKPolarity = SPI_POLARITY_HIGH;
  hspi1.Init.CLKPhase = SPI_PHASE_2EDGE;
  hspi1.Init.NSS = SPI_NSS_SOFT;
  hspi1.Init.BaudRatePrescaler = SPI_BAUDRATEPRESCALER_8;
  hspi1.Init.FirstBit = SPI_FIRSTBIT_MSB;
  hspi1.Init.TIMode = SPI_TIMODE_DISABLE;
  hspi1.Init.CRCCalculation = SPI_CRCCALCULATION_DISABLE;
  hspi1.Init.CRCPolynomial = 10;
  if (HAL_SPI_Init(&hspi1) != HAL_OK)
  {
    Error_Handler();
  }

}

static void MX_SPI2_Init(void)
{

  /* SPI2 parameter configuration*/
  hspi2.Instance = SPI2;
  hspi2.Init.Mode = SPI_MODE_MASTER;
  hspi2.Init.Direction = SPI_DIRECTION_2LINES;
  hspi2.Init.DataSize = SPI_DATASIZE_8BIT;
  hspi2.Init.CLKPolarity = SPI_POLARITY_LOW;
  hspi2.Init.CLKPhase = SPI_PHASE_1EDGE;
  hspi2.Init.NSS = SPI_NSS_SOFT;
  hspi2.Init.BaudRatePrescaler = SPI_BAUDRATEPRESCALER_16;
  hspi2.Init.FirstBit = SPI_FIRSTBIT_MSB;
  hspi2.Init.TIMode = SPI_TIMODE_DISABLE;
  hspi2.Init.CRCCalculation = SPI_CRCCALCULATION_DISABLE;
  hspi2.Init.CRCPolynomial = 10;
  if (HAL_SPI_Init(&hspi2) != HAL_OK)
  {
    Error_Handler();
  }

}

static void MX_SPI3_Init(void)
{

  /* SPI3 parameter configuration*/
  hspi3.Instance = SPI3;
  hspi3.Init.Mode = SPI_MODE_MASTER;
  hspi3.Init.Direction = SPI_DIRECTION_2LINES;
  hspi3.Init.DataSize = SPI_DATASIZE_8BIT;
  hspi3.Init.CLKPolarity = SPI_POLARITY_LOW;
  hspi3.Init.CLKPhase = SPI_PHASE_2EDGE;
  hspi3.Init.NSS = SPI_NSS_SOFT;
  hspi3.Init.BaudRatePrescaler = SPI_BAUDRATEPRESCALER_4;
  hspi3.Init.FirstBit = SPI_FIRSTBIT_MSB;
  hspi3.Init.TIMode = SPI_TIMODE_DISABLE;
  hspi3.Init.CRCCalculation = SPI_CRCCALCULATION_DISABLE;
  hspi3.Init.CRCPolynomial = 10;
  if (HAL_SPI_Init(&hspi3) != HAL_OK)
  {
    Error_Handler();
  }

}

static void MX_SPI4_Init(void)
{

  /* SPI4 parameter configuration*/
  hspi4.Instance = SPI4;
  hspi4.Init.Mode = SPI_MODE_MASTER;
  hspi4.Init.Direction = SPI_DIRECTION_2LINES;
  hspi4.Init.DataSize = SPI_DATASIZE_8BIT;
  hspi4.Init.CLKPolarity = SPI_POLARITY_LOW;
  hspi4.Init.CLKPhase = SPI_PHASE_1EDGE;
  hspi4.Init.NSS = SPI_NSS_SOFT;
  hspi4.Init.BaudRatePrescaler = SPI_BAUDRATEPRESCALER_8;
  hspi4.Init.FirstBit = SPI_FIRSTBIT_MSB;
  hspi4.Init.TIMode = SPI_TIMODE_DISABLE;
  hspi4.Init.CRCCalculation = SPI_CRCCALCULATION_DISABLE;
  hspi4.Init.CRCPolynomial = 10;
  if (HAL_SPI_Init(&hspi4) != HAL_OK)
  {
    Error_Handler();
  }

}

static void MX_TIM1_Init(void)
{

  TIM_ClockConfigTypeDef sClockSourceConfig = {0};
  TIM_MasterConfigTypeDef sMasterConfig = {0};
  TIM_OC_InitTypeDef sConfigOC = {0};
  TIM_BreakDeadTimeConfigTypeDef sBreakDeadTimeConfig = {0};

  htim1.Instance = TIM1;
  htim1.Init.Prescaler = 0;
  htim1.Init.CounterMode = TIM_COUNTERMODE_UP;
  htim1.Init.Period = 22;
  htim1.Init.ClockDivision = TIM_CLOCKDIVISION_DIV1;
  htim1.Init.RepetitionCounter = 0;
  htim1.Init.AutoReloadPreload = TIM_AUTORELOAD_PRELOAD_DISABLE;
  if (HAL_TIM_Base_Init(&htim1) != HAL_OK)
  {
    Error_Handler();
  }
  sClockSourceConfig.ClockSource = TIM_CLOCKSOURCE_INTERNAL;
  if (HAL_TIM_ConfigClockSource(&htim1, &sClockSourceConfig) != HAL_OK)
  {
    Error_Handler();
  }
  if (HAL_TIM_PWM_Init(&htim1) != HAL_OK)
  {
    Error_Handler();
  }
  sMasterConfig.MasterOutputTrigger = TIM_TRGO_RESET;
  sMasterConfig.MasterSlaveMode = TIM_MASTERSLAVEMODE_DISABLE;
  if (HAL_TIMEx_MasterConfigSynchronization(&htim1, &sMasterConfig) != HAL_OK)
  {
    Error_Handler();
  }
  sConfigOC.OCMode = TIM_OCMODE_PWM1;
  sConfigOC.Pulse = 11;
  sConfigOC.OCPolarity = TIM_OCPOLARITY_HIGH;
  sConfigOC.OCNPolarity = TIM_OCNPOLARITY_HIGH;
  sConfigOC.OCFastMode = TIM_OCFAST_DISABLE;
  sConfigOC.OCIdleState = TIM_OCIDLESTATE_RESET;
  sConfigOC.OCNIdleState = TIM_OCNIDLESTATE_RESET;
  if (HAL_TIM_PWM_ConfigChannel(&htim1, &sConfigOC, TIM_CHANNEL_1) != HAL_OK)
  {
    Error_Handler();
  }
  sBreakDeadTimeConfig.OffStateRunMode = TIM_OSSR_DISABLE;
  sBreakDeadTimeConfig.OffStateIDLEMode = TIM_OSSI_DISABLE;
  sBreakDeadTimeConfig.LockLevel = TIM_LOCKLEVEL_OFF;
  sBreakDeadTimeConfig.DeadTime = 0;
  sBreakDeadTimeConfig.BreakState = TIM_BREAK_DISABLE;
  sBreakDeadTimeConfig.BreakPolarity = TIM_BREAKPOLARITY_HIGH;
  sBreakDeadTimeConfig.AutomaticOutput = TIM_AUTOMATICOUTPUT_DISABLE;
  if (HAL_TIMEx_ConfigBreakDeadTime(&htim1, &sBreakDeadTimeConfig) != HAL_OK)
  {
    Error_Handler();
  }
  HAL_TIM_MspPostInit(&htim1);

}

static void MX_TIM3_Init(void)
{

  TIM_ClockConfigTypeDef sClockSourceConfig = {0};
  TIM_MasterConfigTypeDef sMasterConfig = {0};

  htim3.Instance = TIM3;
  htim3.Init.Prescaler = 89;
  htim3.Init.CounterMode = TIM_COUNTERMODE_UP;
  htim3.Init.Period = 99;
  htim3.Init.ClockDivision = TIM_CLOCKDIVISION_DIV1;
  htim3.Init.AutoReloadPreload = TIM_AUTORELOAD_PRELOAD_DISABLE;
  if (HAL_TIM_Base_Init(&htim3) != HAL_OK)
  {
    Error_Handler();
  }
  sClockSourceConfig.ClockSource = TIM_CLOCKSOURCE_INTERNAL;
  if (HAL_TIM_ConfigClockSource(&htim3, &sClockSourceConfig) != HAL_OK)
  {
    Error_Handler();
  }
  sMasterConfig.MasterOutputTrigger = TIM_TRGO_RESET;
  sMasterConfig.MasterSlaveMode = TIM_MASTERSLAVEMODE_DISABLE;
  if (HAL_TIMEx_MasterConfigSynchronization(&htim3, &sMasterConfig) != HAL_OK)
  {
    Error_Handler();
  }

}

static void MX_TIM9_Init(void)
{

  TIM_ClockConfigTypeDef sClockSourceConfig = {0};

  htim9.Instance = TIM9;
  htim9.Init.Prescaler = 0;
  htim9.Init.CounterMode = TIM_COUNTERMODE_UP;
  htim9.Init.Period = 65535;
  htim9.Init.ClockDivision = TIM_CLOCKDIVISION_DIV1;
  htim9.Init.AutoReloadPreload = TIM_AUTORELOAD_PRELOAD_DISABLE;
  if (HAL_TIM_Base_Init(&htim9) != HAL_OK)
  {
    Error_Handler();
  }
  sClockSourceConfig.ClockSource = TIM_CLOCKSOURCE_INTERNAL;
  if (HAL_TIM_ConfigClockSource(&htim9, &sClockSourceConfig) != HAL_OK)
  {
    Error_Handler();
  }

}

static void MX_TIM10_Init(void)
{

  htim10.Instance = TIM10;
  htim10.Init.Prescaler = 180-1;
  htim10.Init.CounterMode = TIM_COUNTERMODE_UP;
  htim10.Init.Period = 59999;
  htim10.Init.ClockDivision = TIM_CLOCKDIVISION_DIV1;
  htim10.Init.AutoReloadPreload = TIM_AUTORELOAD_PRELOAD_DISABLE;
  if (HAL_TIM_Base_Init(&htim10) != HAL_OK)
  {
    Error_Handler();
  }

}

static void MX_TIM11_Init(void)
{

  htim11.Instance = TIM11;
  htim11.Init.Prescaler = 0;
  htim11.Init.CounterMode = TIM_COUNTERMODE_UP;
  htim11.Init.Period = 65535;
  htim11.Init.ClockDivision = TIM_CLOCKDIVISION_DIV1;
  htim11.Init.AutoReloadPreload = TIM_AUTORELOAD_PRELOAD_DISABLE;
  if (HAL_TIM_Base_Init(&htim11) != HAL_OK)
  {
    Error_Handler();
  }

}

static void MX_TIM12_Init(void)
{

  TIM_ClockConfigTypeDef sClockSourceConfig = {0};

  htim12.Instance = TIM12;
  htim12.Init.Prescaler = 0;
  htim12.Init.CounterMode = TIM_COUNTERMODE_UP;
  htim12.Init.Period = 65535;
  htim12.Init.ClockDivision = TIM_CLOCKDIVISION_DIV1;
  htim12.Init.AutoReloadPreload = TIM_AUTORELOAD_PRELOAD_DISABLE;
  if (HAL_TIM_Base_Init(&htim12) != HAL_OK)
  {
    Error_Handler();
  }
  sClockSourceConfig.ClockSource = TIM_CLOCKSOURCE_INTERNAL;
  if (HAL_TIM_ConfigClockSource(&htim12, &sClockSourceConfig) != HAL_OK)
  {
    Error_Handler();
  }

}

static void MX_USART1_UART_Init(void)
{

  huart1.Instance = USART1;
  huart1.Init.BaudRate = 115200;
  huart1.Init.WordLength = UART_WORDLENGTH_8B;
  huart1.Init.StopBits = UART_STOPBITS_1;
  huart1.Init.Parity = UART_PARITY_NONE;
  huart1.Init.Mode = UART_MODE_TX_RX;
  huart1.Init.HwFlowCtl = UART_HWCONTROL_NONE;
  huart1.Init.OverSampling = UART_OVERSAMPLING_16;
  if (HAL_UART_Init(&huart1) != HAL_OK)
  {
    Error_Handler();
  }

}

static void MX_USART2_UART_Init(void)
{

  huart2.Instance = USART2;
  huart2.Init.BaudRate = 19200;
  huart2.Init.WordLength = UART_WORDLENGTH_8B;
  huart2.Init.StopBits = UART_STOPBITS_1;
  huart2.Init.Parity = UART_PARITY_NONE;
  huart2.Init.Mode = UART_MODE_TX_RX;
  huart2.Init.HwFlowCtl = UART_HWCONTROL_NONE;
  huart2.Init.OverSampling = UART_OVERSAMPLING_16;
  if (HAL_UART_Init(&huart2) != HAL_OK)
  {
    Error_Handler();
  }

}

static void MX_USART3_UART_Init(void)
{

  huart3.Instance = USART3;
  huart3.Init.BaudRate = 19200;
  huart3.Init.WordLength = UART_WORDLENGTH_8B;
  huart3.Init.StopBits = UART_STOPBITS_1;
  huart3.Init.Parity = UART_PARITY_NONE;
  huart3.Init.Mode = UART_MODE_TX_RX;
  huart3.Init.HwFlowCtl = UART_HWCONTROL_NONE;
  huart3.Init.OverSampling = UART_OVERSAMPLING_16;
  if (HAL_UART_Init(&huart3) != HAL_OK)
  {
    Error_Handler();
  }

}

static void MX_DMA_Init(void)
{

  /* DMA controller clock enable */
  __HAL_RCC_DMA2_CLK_ENABLE();
  __HAL_RCC_DMA1_CLK_ENABLE();

  /* DMA interrupt init */
  /* DMA1_Stream1_IRQn interrupt configuration */
  HAL_NVIC_SetPriority(DMA1_Stream1_IRQn, 5, 0);
  HAL_NVIC_EnableIRQ(DMA1_Stream1_IRQn);
  /* DMA1_Stream4_IRQn interrupt configuration */
  HAL_NVIC_SetPriority(DMA1_Stream4_IRQn, 5, 0);
  HAL_NVIC_EnableIRQ(DMA1_Stream4_IRQn);
  /* DMA2_Stream0_IRQn interrupt configuration */
  HAL_NVIC_SetPriority(DMA2_Stream0_IRQn, 5, 0);
  HAL_NVIC_EnableIRQ(DMA2_Stream0_IRQn);

}

static void MX_GPIO_Init(void)
{
  GPIO_InitTypeDef GPIO_InitStruct = {0};

  /* GPIO Ports Clock Enable */
  __HAL_RCC_GPIOE_CLK_ENABLE();
  __HAL_RCC_GPIOC_CLK_ENABLE();
  __HAL_RCC_GPIOH_CLK_ENABLE();
  __HAL_RCC_GPIOA_CLK_ENABLE();
  __HAL_RCC_GPIOB_CLK_ENABLE();
  __HAL_RCC_GPIOD_CLK_ENABLE();
  HAL_GPIO_WritePin(GPIOE, SPI2_CS_FLASH_Pin | SPI2_CS_MOTOR_Pin, GPIO_PIN_SET);

  /*Configure GPIO pin Output Level */
  HAL_GPIO_WritePin(GPIOE, SPI1_CS_DAC_Pin|LED1_Pin|PFO_O_Pin
                          |DATAOUT_Pin|LED2_Pin, GPIO_PIN_RESET);

  /*Configure GPIO pin Output Level */
  HAL_GPIO_WritePin(GPIOC, O_LOCK_INTERFACE_OPEN_Pin|DAC_LDAC_Pin|DISPLAY_STCP_Pin|O_LOCK_POWER_OPEN_Pin, GPIO_PIN_RESET);

  /*Configure GPIO pin Output Level */
  HAL_GPIO_WritePin(GPIOA, KEY_Pin|SPI3_CS_ADC_Pin|LOCK_POWER_CLOSE_Pin, GPIO_PIN_RESET);

  /*Configure GPIO pin Output Level */
  HAL_GPIO_WritePin(GPIOB, CONTROL_Pin|CLKS_Pin|SPI4_CS_EEPROM_Pin|I_DEVICETYPE_3_Pin
                          |I_DEVICETYPE_2_Pin|ARISWITCH_Pin|SYSTEM_LED_Pin, GPIO_PIN_RESET);

  /*Configure GPIO pin Output Level */
  HAL_GPIO_WritePin(GPIOD, O_FAN_Pin|DISPLAY_DS_Pin|LED3_Pin|LED4_Pin
                          |USART1_CTRL_Pin|O_LOCK_INTERFACE_CLOSE_Pin|USART2_CTRL_Pin|SPI1_CS_ECAT_Pin, GPIO_PIN_RESET);

  /*Configure GPIO pins : SPI1_CS_DAC_Pin O_USB_DP_CTRL_Pin LED1_Pin PFO_O_Pin
                           DATAOUT_Pin SPI2_CS_FLASH_Pin LED2_Pin SPI2_CS_MOTOR_Pin */
  GPIO_InitStruct.Pin = SPI1_CS_DAC_Pin|LED1_Pin|PFO_O_Pin
                          |DATAOUT_Pin|LED2_Pin;
  GPIO_InitStruct.Mode = GPIO_MODE_OUTPUT_PP;
  GPIO_InitStruct.Pull = GPIO_NOPULL;
  GPIO_InitStruct.Speed = GPIO_SPEED_FREQ_LOW;
  HAL_GPIO_Init(GPIOE, &GPIO_InitStruct);

  GPIO_InitStruct.Pin = O_USB_DP_CTRL_Pin;
  GPIO_InitStruct.Mode = GPIO_MODE_INPUT;
  GPIO_InitStruct.Pull = GPIO_NOPULL;
  HAL_GPIO_Init(GPIOE, &GPIO_InitStruct);
  GPIO_InitStruct.Pin = SPI2_CS_FLASH_Pin | SPI2_CS_MOTOR_Pin;
  GPIO_InitStruct.Mode = GPIO_MODE_OUTPUT_PP;
  HAL_GPIO_Init(GPIOE, &GPIO_InitStruct);

  /*Configure GPIO pins : MOTOR_EN_SIGNAL_IN_Pin PFO_I_Pin EEPROM_Loaded_Pin */
  GPIO_InitStruct.Pin = MOTOR_EN_SIGNAL_IN_Pin|PFO_I_Pin|EEPROM_Loaded_Pin;
  GPIO_InitStruct.Mode = GPIO_MODE_INPUT;
  GPIO_InitStruct.Pull = GPIO_NOPULL;
  HAL_GPIO_Init(GPIOE, &GPIO_InitStruct);

  /*Configure GPIO pins : I_LOCK_POWER_OPEN_Pin I_LOCK_POWER_CLOSE_Pin I_LOCK_INTERFACE_CLOSE_Pin I_LOCK_INTERFACE_OPEN_Pin */
  GPIO_InitStruct.Pin = I_LOCK_POWER_OPEN_Pin|I_LOCK_POWER_CLOSE_Pin|I_LOCK_INTERFACE_CLOSE_Pin|I_LOCK_INTERFACE_OPEN_Pin;
  GPIO_InitStruct.Mode = GPIO_MODE_INPUT;
  GPIO_InitStruct.Pull = GPIO_NOPULL;
  HAL_GPIO_Init(GPIOC, &GPIO_InitStruct);

  /*Configure GPIO pins : O_LOCK_INTERFACE_OPEN_Pin DAC_LDAC_Pin DISPLAY_STCP_Pin O_LOCK_POWER_OPEN_Pin */
  GPIO_InitStruct.Pin = O_LOCK_INTERFACE_OPEN_Pin|DAC_LDAC_Pin|DISPLAY_STCP_Pin|O_LOCK_POWER_OPEN_Pin;
  GPIO_InitStruct.Mode = GPIO_MODE_OUTPUT_PP;
  GPIO_InitStruct.Pull = GPIO_NOPULL;
  GPIO_InitStruct.Speed = GPIO_SPEED_FREQ_LOW;
  HAL_GPIO_Init(GPIOC, &GPIO_InitStruct);

  /*Configure GPIO pins : KEY_Pin SPI3_CS_ADC_Pin LOCK_POWER_CLOSE_Pin */
  GPIO_InitStruct.Pin = KEY_Pin|SPI3_CS_ADC_Pin|LOCK_POWER_CLOSE_Pin;
  GPIO_InitStruct.Mode = GPIO_MODE_OUTPUT_PP;
  GPIO_InitStruct.Pull = GPIO_NOPULL;
  GPIO_InitStruct.Speed = GPIO_SPEED_FREQ_LOW;
  HAL_GPIO_Init(GPIOA, &GPIO_InitStruct);

  /*Configure GPIO pins : DISPLAY_SHCP_Pin AD_READY_INT_Pin */
  GPIO_InitStruct.Pin = DISPLAY_SHCP_Pin|AD_READY_INT_Pin;
  GPIO_InitStruct.Mode = GPIO_MODE_IT_RISING;
  GPIO_InitStruct.Pull = GPIO_NOPULL;
  HAL_GPIO_Init(GPIOC, &GPIO_InitStruct);

  /*Configure GPIO pins : CONTROL_Pin CLKS_Pin SPI4_CS_EEPROM_Pin I_DEVICETYPE_3_Pin
                           I_DEVICETYPE_2_Pin ARISWITCH_Pin SYSTEM_LED_Pin */
  GPIO_InitStruct.Pin = CONTROL_Pin|CLKS_Pin|SPI4_CS_EEPROM_Pin|I_DEVICETYPE_3_Pin
                          |I_DEVICETYPE_2_Pin|ARISWITCH_Pin|SYSTEM_LED_Pin;
  GPIO_InitStruct.Mode = GPIO_MODE_OUTPUT_PP;
  GPIO_InitStruct.Pull = GPIO_NOPULL;
  GPIO_InitStruct.Speed = GPIO_SPEED_FREQ_LOW;
  HAL_GPIO_Init(GPIOB, &GPIO_InitStruct);

  /*Configure GPIO pin : DATAIN_Pin */
  GPIO_InitStruct.Pin = DATAIN_Pin;
  GPIO_InitStruct.Mode = GPIO_MODE_INPUT;
  GPIO_InitStruct.Pull = GPIO_NOPULL;
  HAL_GPIO_Init(DATAIN_GPIO_Port, &GPIO_InitStruct);

  /*Configure GPIO pins : O_FAN_Pin DISPLAY_DS_Pin LED3_Pin LED4_Pin
                           USART1_CTRL_Pin USART2_CTRL_Pin SPI1_CS_ECAT_Pin */
  GPIO_InitStruct.Pin = O_FAN_Pin|DISPLAY_DS_Pin|LED3_Pin|LED4_Pin
                          |USART1_CTRL_Pin|USART2_CTRL_Pin|SPI1_CS_ECAT_Pin;
  GPIO_InitStruct.Mode = GPIO_MODE_OUTPUT_PP;
  GPIO_InitStruct.Pull = GPIO_NOPULL;
  GPIO_InitStruct.Speed = GPIO_SPEED_FREQ_LOW;
  HAL_GPIO_Init(GPIOD, &GPIO_InitStruct);

  /*Configure GPIO pin : I_DEVICETYPE_1_Pin */
  GPIO_InitStruct.Pin = I_DEVICETYPE_1_Pin;
  GPIO_InitStruct.Mode = GPIO_MODE_INPUT;
  GPIO_InitStruct.Pull = GPIO_NOPULL;
  HAL_GPIO_Init(I_DEVICETYPE_1_GPIO_Port, &GPIO_InitStruct);

  /*Configure GPIO pin : O_LOCK_INTERFACE_CLOSE_Pin */
  GPIO_InitStruct.Pin = O_LOCK_INTERFACE_CLOSE_Pin;
  GPIO_InitStruct.Mode = GPIO_MODE_OUTPUT_PP;
  GPIO_InitStruct.Pull = GPIO_PULLUP;
  GPIO_InitStruct.Speed = GPIO_SPEED_FREQ_LOW;
  HAL_GPIO_Init(O_LOCK_INTERFACE_CLOSE_GPIO_Port, &GPIO_InitStruct);

  /*Configure GPIO pin : ECAT_SYNCO_INT_Pin */
  GPIO_InitStruct.Pin = ECAT_SYNCO_INT_Pin;
  GPIO_InitStruct.Mode = GPIO_MODE_IT_RISING;
  GPIO_InitStruct.Pull = GPIO_NOPULL;
  HAL_GPIO_Init(ECAT_SYNCO_INT_GPIO_Port, &GPIO_InitStruct);

  /*Configure GPIO pin : INT_ESC_Pin */
  GPIO_InitStruct.Pin = INT_ESC_Pin;
  GPIO_InitStruct.Mode = GPIO_MODE_IT_RISING;
  GPIO_InitStruct.Pull = GPIO_NOPULL;
  HAL_GPIO_Init(INT_ESC_GPIO_Port, &GPIO_InitStruct);

}

__weak void StartDefaultTask(void *argument)
{
  for(;;)
  {
    osDelay(1);
  }
}

__weak void StartTask03(void *argument)
{
  for(;;)
  {
    osDelay(1);
  }
}

__weak void TASK_RS485(void *argument)
{
  /* USER CODE BEGIN TASK_RS485 */
  /* Infinite loop */
  for(;;)
  {
/* 	  if (MAIN_ucSerialRxTxFlag==1) {
		  API_GetSerialRxData(MAIN_ucSerialRxBuff,&MAIN_ucSerialRxTxSize,&MAIN_ucSerialRxTxFlag);
		  CheckSerial(1);
	  }
	  API_SetSerialTxData(MAIN_ucSerialTxBuff,&MAIN_ucSerialRxTxSize,&MAIN_ucSerialRxTxFlag);
 */
	  osDelay(1);
  }
  /* USER CODE END TASK_RS485 */
}

__weak void TASK_DeviceNet(void *argument)
{
  for(;;)
  {
    osDelay(1);
  }
}

__weak void Task_Hcms(void *argument)
{
  for(;;)
  {
    osDelay(1);
  }
}

__weak void TASK_RS232(void *argument)
{
  for(;;)
  {
    osDelay(1);
  }
}

__weak void Task_FlowEst(void *argument)
{
  for(;;)
  {
    osDelay(1);
  }
}

__weak void Task_Adapyive(void *argument)
{
  for(;;)
  {
    osDelay(1);
  }
}

__weak void TASK_EtherCAT(void *argument)
{
  for(;;)
  {
    osDelay(1);
  }
}

__weak void TASK_RS485_2(void *argument)
{
  for(;;)
  {
    osDelay(1);
  }
}

__weak void TASK_USB(void *argument)
{
  /* USER CODE BEGIN TASK_USB */
  (void)argument;
  usb_media_lock();
  usb_app_init();
  usb_media_unlock();
  usb_app_ready = true;
  for (;;) {
    usb_media_lock();
    usb_app_task();
    usb_media_unlock();
    g_usb_min_heap = xPortGetMinimumEverFreeHeapSize();
    g_usb_worker_stack_free = uxTaskGetStackHighWaterMark(NULL) * sizeof(StackType_t);
    if ((uint32_t)(HAL_GetTick() - usb_io_progress) < 1000u) board_watchdog_refresh();
    osDelay(1);
  }
  /* USER CODE END TASK_USB */
}

void TASK_USB_IO(void *argument)
{
  /* USER CODE BEGIN TASK_USB_IO */
  (void)argument;
  while (!usb_app_ready) osDelay(1);
  if (!usb_io_stack_init()) Error_Handler();
  for (;;) {
    usb_io_task();
    usb_io_progress = HAL_GetTick();
    g_usb_io_stack_free = uxTaskGetStackHighWaterMark(NULL) * sizeof(StackType_t);
    osDelay(1);
  }
  /* USER CODE END TASK_USB_IO */
}

void HAL_TIM_PeriodElapsedCallback(TIM_HandleTypeDef *htim)
{
  if (htim->Instance == TIM7) {
    HAL_IncTick();
  }
}

void Error_Handler(void)
{
  __disable_irq();
  while (1)
  {
  }
}
